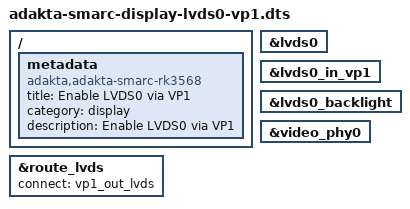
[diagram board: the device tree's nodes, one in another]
/dts-v1/;
/plugin/;

/ {
	metadata {
		title = "Enable LVDS0 via VP1";
		compatible = "adakta,adakta-smarc-rk3568";
		category = "display";
		description = "Enable LVDS0 via VP1";
	};

	fragment@0 {
		target = <&lvds0>;

		__overlay__ {
			status = "okay";
		};
	};

	fragment@1 {
		target = <&lvds0_in_vp1>;

		__overlay__ {
			status = "okay";
		};
	};

	fragment@2 {
		target = <&route_lvds>;

		__overlay__ {
			status = "okay";
			connect = <&vp1_out_lvds>;
		};
	};

	fragment@3 {
		target = <&lvds0_backlight>;

		__overlay__ {
			status = "okay";
		};
	};

	fragment@4 {
		target = <&video_phy0>;

		__overlay__ {
			status = "okay";
		};
	};
};
